# ARMv7-M-MPU register map
Registers from a debugger description file.
Registers are 32-bit, access not given, no defined reset value unless marked. A register's access mark holds for its fields unless they carry their own. Addresses are absolute; registers are grouped by the start of their names; lines under a group give offsets from that group; [hi:lo] are bit positions; {n}, {i} and the like mark numbered series; 'fields as' and 'values as' point back to an identical list; <NAME> marks a mode.

## MPU
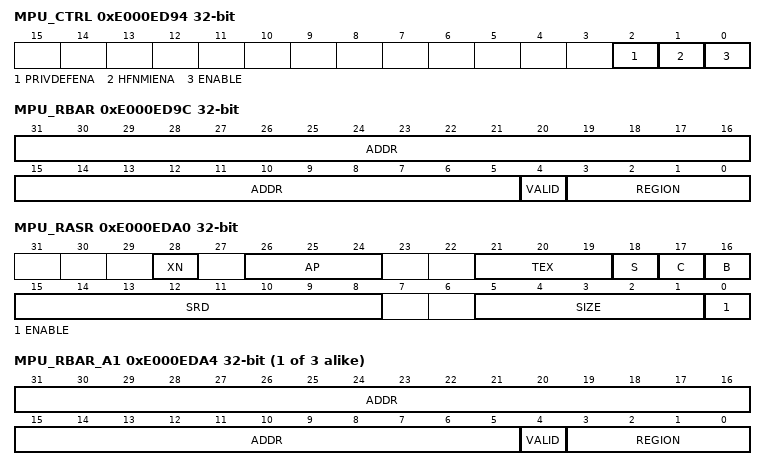
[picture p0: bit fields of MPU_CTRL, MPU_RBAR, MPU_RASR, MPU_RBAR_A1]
0xE000ED94 MPU_CTRL — MPU Control Register
  [2] PRIVDEFENA — When the ENABLE bit is set to 1, the meaning of this bit is: 0: Disables the default memory map. Any instruction or data access that does not access a defined region faults. 1: Enables the default memory map as a background region for privileged access. The background region acts as region number -1. All memory regions configured in the MPU take priority over the default memory map. When the ENABLE bit is set to 0, the processor ignores the PRIVDEFENA bit. If no regions are enabled and the PRIVDEFENA and ENABLE bits are set to 1, only privileged code can execute from the system address map.
  [1] HFNMIENA — When the ENABLE bit is set to 1, controls whether handlers executing with priority less than 0 access memory with the MPU enabled or with the MPU disabled. This applies to HardFaults, NMIs, and exception handlers when FAULTMASK is set to 1. 0: Disables the MPU for these handlers. 1: Use the MPU for memory accesses by these handlers. If HFNMIENA is set to 1 when ENABLE is set to 0, behavior is unpredictable.
  [0] ENABLE — Enables the MPU. 0: The MPU is disabled. 1: The MPU is enabled.
0xE000ED98 MPU_RNR — MPU Region Number Register
  [7:0] REGION — Indicates the memory region accessed by MPU_RBAR and MPU_RASR.
0xE000ED9C MPU_RBAR — MPU Base Address Register
  [31:5] ADDR — Base address of the region.
  [4] VALID — On writes, indicates whether the region to update is specified by MPU_RNR.REGION, or by the REGION value specified in this write. When using the REGION value specified by this write, MPU_RNR.REGION is updated to this value. 0: Apply the base address update to the region specified by MPU_RNR.REGION. The REGION field value is ignored. 1: Update MPU_RNR.REGION to the value obtained by zero extending the REGION value specified in this write, and apply the base address update to this region. This bit reads as zero.
  [3:0] REGION — On writes, can specify the number of the region to update, see VALID field description. On reads, returns bits[3:0] of MPU_RNR.
0xE000EDA0 MPU_RASR — MPU Region Attribute Register
  [28] XN — Execute Never. Indicates whether the processor can execute instructions from the region. 0: Execution of an instruction fetched from this region permitted. 1: Execution of an instruction fetched from this region not permitted.
  [26:24] AP — Access permissions. Indicate the access and privilege properties of the region. 0x0: Any access generates a permission fault. 0x1: Privileged access only. 0x2: Any unprivileged write generates a permission fault. 0x3: Full access. 0x4: Reserved. 0x5: Privileged read-only. 0x6: Privileged and unprivileged read-only. 0x7: Privileged and unprivileged read-only.
  [21:19] TEX — Type extension. The TEX, C, and B fields together indicate the memory type of the region, and: — For Normal memory, the cacheable properties of the region. — For Device memory, whether the region is shareable.
  [18] S — Shareable. For Normal memory regions, indicates whether the region is shareable.
  [17] C — Cacheable. The TEX, C, and B fields together indicate the memory type of the region, and: — For Normal memory, the cacheable properties of the region. — For Device memory, whether the region is shareable.
  [16] B — Bufferable. The TEX, C, and B fields together indicate the memory type of the region, and: — For Normal memory, the cacheable properties of the region. — For Device memory, whether the region is shareable.
  [15:8] SRD — Subregion Disable. For regions of 256 bytes or larger, each bit of this field controls whether one of the eight equal subregions is enabled. 0: Subregion enabled. 1: Subregion disabled.
  [5:1] SIZE — Indicates the region size. The region size, in bytes, is 2^(SIZE+1). SIZE field values less than 4 are reserved, because the smallest supported region size is 32 bytes.
  [0] ENABLE — Enables this region. 0: When the MPU is enabled, this region is disabled. 1: When the MPU is enabled, this region is enabled. Enabling a region has no effect unless the MPU_CTRL.ENABLE bit is set to 1, to enable the MPU.
{0xE000ED9C+8i} MPU_RBAR_A{i} (i=1..3) — MPU Base Address Register Alias {i}
  fields as MPU_RBAR
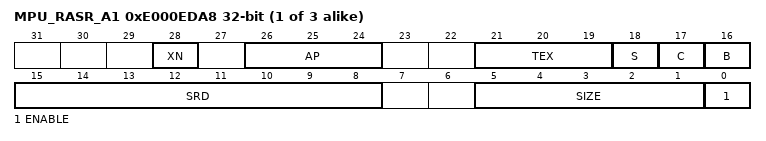
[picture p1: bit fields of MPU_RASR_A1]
{0xE000EDA0+8i} MPU_RASR_A{i} (i=1..3) — MPU Region Attribute Register Alias {i}
  fields as MPU_RASR
